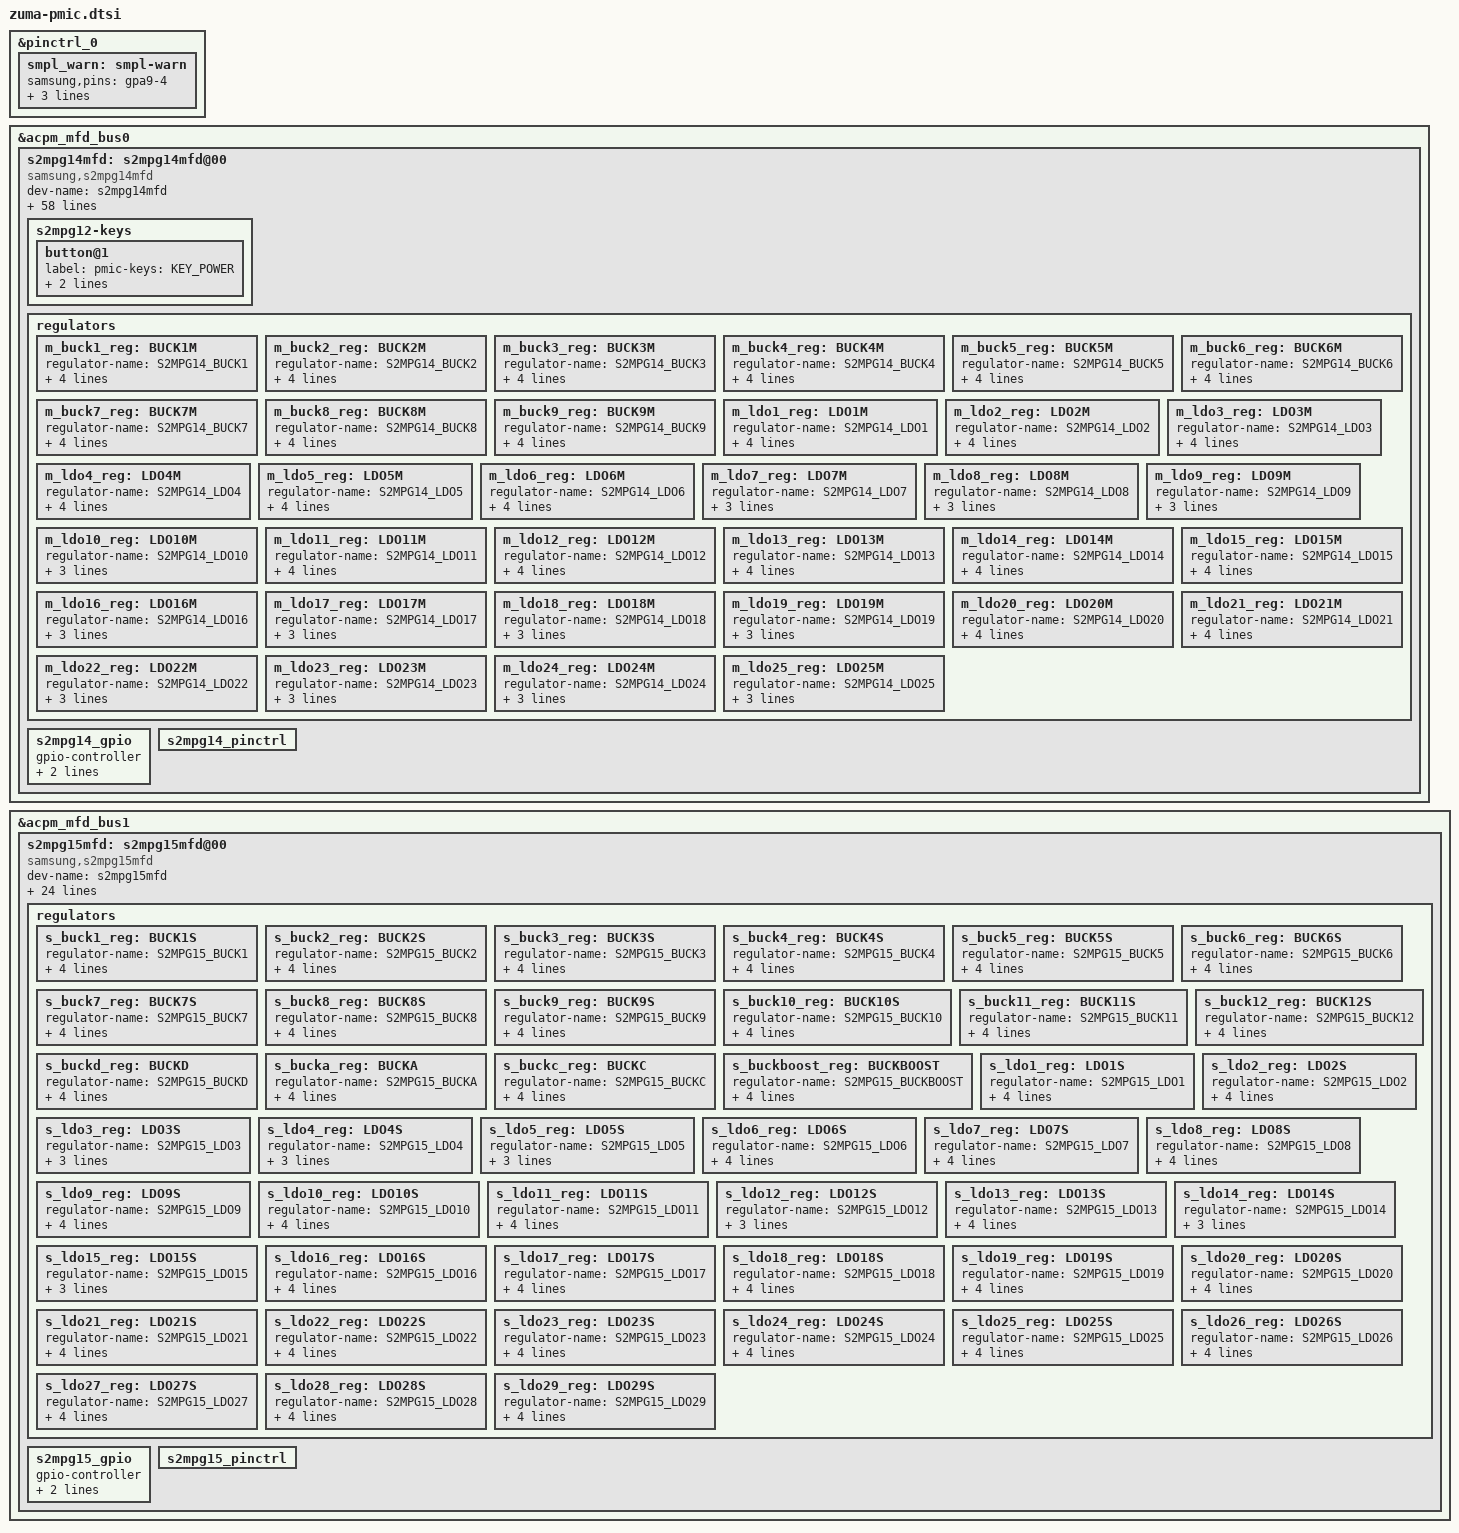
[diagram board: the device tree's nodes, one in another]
// SPDX-License-Identifier: GPL-2.0-only
/*
 * zuma pmic device tree source
 *
 * Copyright 2022 Google LLC.
 *
 */

#include <dt-bindings/power/google-power.h>
#include <dt-bindings/power/s2mpg1x-power.h>
#include <dt-bindings/regulator/samsung,s2mpg-regulator.h>

&pinctrl_0 {
	smpl_warn: smpl-warn {
		samsung,pins = "gpa9-4";
		samsung,pin-function = <EXYNOS_PIN_FUNC_EINT>;
		samsung,pin-pud = <EXYNOS_PIN_PULL_NONE>;
		samsung,pin-drv = <GS101_PIN_DRV_2_5_MA>;
	};
};

&acpm_mfd_bus0 {
	#address-cells = <1>;
	#size-cells = <0>;
	status = "okay";
	s2mpg14mfd: s2mpg14mfd@00 {
		compatible = "samsung,s2mpg14mfd";
		dev-name = "s2mpg14mfd";
		acpm-ipc-channel = <2>;
		acpm-speedy-channel = <0>;
		s2mpg14,wakeup = "enabled";
		reg = <0x1f>;
		interrupts = <1 0 0>, // SMPL_WARN
			     <1 0 1>, // OCP_WARN_CPUCL1
			     <1 0 2>, // OCP_WARN_CPUCL2
			     <1 0 3>, // SOFT_OCP_WARN_CPUCL1
			     <1 0 4>, // SOFT_OCP_WARN_CPUCL2
			     <1 0 5>, // OCP_WARN_TPU
			     <1 0 6>; // SOFT_OCP_WARN_TPU
		interrupt-parent = <&gpa0>;
		pinctrl-names = "default";
		pinctrl-0 = <&smpl_warn>;
		gpios = <&gpa9 4 GPIO_ACTIVE_HIGH>;

		#thermal-sensor-cells = <1>;

		/* SMPL_WARN */
		smpl_warn_en = <1>; /* 1 : enable , 0 : disable */
		smpl_warn_vth = <SMPL_2_9V>;
		/* SMPL_Hys[4:3] 00(Reserved), 01(200mV) */
		/*		 10(300mV), 11(Reserved) */
		smpl_warn_hys = <SMPL_HYST_200MV>;

		b2_ocp_warn_en = <OCP_WARN_DISABLE>;
		b2_ocp_warn_cnt = <OCP_WARN_2_CLOCK>;
		b2_ocp_warn_dvs_mask = <OCP_WARN_NOT_MASKED>;
		b2_ocp_warn_lvl = <OCP_WARN_LVL_2PH_8_A>;

		b3_ocp_warn_en = <OCP_WARN_DISABLE>;
		b3_ocp_warn_cnt = <OCP_WARN_2_CLOCK>;
		b3_ocp_warn_dvs_mask = <OCP_WARN_NOT_MASKED>;
		b3_ocp_warn_lvl = <OCP_WARN_LVL_3PH_13_50_A>;

		b7_ocp_warn_en = <OCP_WARN_DISABLE>;
		b7_ocp_warn_cnt = <OCP_WARN_2_CLOCK>;
		b7_ocp_warn_dvs_mask = <OCP_WARN_NOT_MASKED>;
		b7_ocp_warn_lvl = <OCP_WARN_LVL_3PH_13_50_A>;

		b2_soft_ocp_warn_en = <OCP_WARN_DISABLE>;
		b2_soft_ocp_warn_cnt = <OCP_WARN_2_CLOCK>;
		b2_soft_ocp_warn_dvs_mask = <OCP_WARN_NOT_MASKED>;
		b2_soft_ocp_warn_lvl = <OCP_WARN_LVL_2PH_8_A>;

		b3_soft_ocp_warn_en = <OCP_WARN_DISABLE>;
		b3_soft_ocp_warn_cnt = <OCP_WARN_2_CLOCK>;
		b3_soft_ocp_warn_dvs_mask = <OCP_WARN_NOT_MASKED>;
		b3_soft_ocp_warn_lvl = <OCP_WARN_LVL_3PH_13_50_A>;

		b7_soft_ocp_warn_en = <OCP_WARN_DISABLE>;
		b7_soft_ocp_warn_cnt = <OCP_WARN_2_CLOCK>;
		b7_soft_ocp_warn_dvs_mask = <OCP_WARN_NOT_MASKED>;
		b7_soft_ocp_warn_lvl = <OCP_WARN_LVL_3PH_13_50_A>;

		/* BUCK OCP Detection */
		buck_ocp_ctrl1 = <0xBB>;
		buck_ocp_ctrl2 = <0xBB>;
		buck_ocp_ctrl3 = <0xBB>;
		buck_ocp_ctrl4 = <0xBB>;
		buck_ocp_ctrl5 = <0xBB>;

		/* RTC: wtsr/smpl */
		wtsr_en = "enabled";
		coldrst_en = "enabled";
		smpl_en = "disabled";
		wtsr_timer_val = <RTC_WTSRT_2_000_SEC>;
		coldrst_timer_val = <RTC_WTSR_COLDTIMER_256_MSEC>;
		smpl_timer_val = <RTC_SMPLT_1_93_SEC>;
		sub_smpl_en = "disabled";
		check_jigon = <0>;

		/* RTC: If first boot, reset rtc to 1/1/2020 12:00:00(Wed) */
		init_time,sec = <0>;
		init_time,min = <0>;
		init_time,hour = <12>;
		init_time,mday = <1>;
		init_time,mon = <0>;
		init_time,year = <120>;
		init_time,wday = <3>;

		/* PCTRLSEL(VGPIO) 1~11 (CONTROL_SEL#) */
		sel_vgpio = <0xD3 0x1C 0xE3 0x01 0x63 0xC6
			0xE1 0x47 0x4D 0x96 0x09>;

		s2mpg12-keys {
			button@1 {
				label = "pmic-keys: KEY_POWER";
				linux,code = <116>;
				wakeup = <1>;
			};
		};

		regulators {
			m_buck1_reg: BUCK1M {
				regulator-name = "S2MPG14_BUCK1";
				regulator-min-microvolt = <450000>;
				regulator-max-microvolt = <1300000>;
				regulator-always-on;
				regulator-initial-mode = <SEC_OPMODE_ON>;
			};

			m_buck2_reg: BUCK2M {
				regulator-name = "S2MPG14_BUCK2";
				regulator-min-microvolt = <450000>;
				regulator-max-microvolt = <1300000>;
				regulator-always-on;
				regulator-initial-mode = <SEC_OPMODE_ON>;
			};

			m_buck3_reg: BUCK3M {
				regulator-name = "S2MPG14_BUCK3";
				regulator-min-microvolt = <450000>;
				regulator-max-microvolt = <1300000>;
				regulator-always-on;
				regulator-initial-mode = <SEC_OPMODE_ON>;
			};

			m_buck4_reg: BUCK4M {
				regulator-name = "S2MPG14_BUCK4";
				regulator-min-microvolt = <450000>;
				regulator-max-microvolt = <1300000>;
				regulator-always-on;
				regulator-initial-mode = <SEC_OPMODE_ON>;
			};

			m_buck5_reg: BUCK5M {
				regulator-name = "S2MPG14_BUCK5";
				regulator-min-microvolt = <450000>;
				regulator-max-microvolt = <1300000>;
				regulator-always-on;
				regulator-initial-mode = <SEC_OPMODE_ON>;
			};

			m_buck6_reg: BUCK6M {
				regulator-name = "S2MPG14_BUCK6";
				regulator-min-microvolt = <450000>;
				regulator-max-microvolt = <1500000>;
				regulator-always-on;
				regulator-initial-mode = <SEC_OPMODE_ON>;
			};

			m_buck7_reg: BUCK7M {
				regulator-name = "S2MPG14_BUCK7";
				regulator-min-microvolt = <450000>;
				regulator-max-microvolt = <1300000>;
				regulator-always-on;
				regulator-initial-mode = <SEC_OPMODE_ON>;
			};

			m_buck8_reg: BUCK8M {
				regulator-name = "S2MPG14_BUCK8";
				regulator-min-microvolt = <450000>;
				regulator-max-microvolt = <1300000>;
				regulator-always-on;
				regulator-initial-mode = <SEC_OPMODE_ON>;
			};

			m_buck9_reg: BUCK9M {
				regulator-name = "S2MPG14_BUCK9";
				regulator-min-microvolt = <450000>;
				regulator-max-microvolt = <1300000>;
				regulator-always-on;
				regulator-initial-mode = <SEC_OPMODE_ON>;
			};

			m_ldo1_reg: LDO1M {
				regulator-name = "S2MPG14_LDO1";
				regulator-min-microvolt = <450000>;
				regulator-max-microvolt = <950000>;
				regulator-always-on;
				regulator-initial-mode = <SEC_OPMODE_ON>;
			};

			m_ldo2_reg: LDO2M {
				regulator-name = "S2MPG14_LDO2";
				regulator-min-microvolt = <1600000>;
				regulator-max-microvolt = <1950000>;
				regulator-always-on;
				regulator-initial-mode = <SEC_OPMODE_ON>;
			};

			m_ldo3_reg: LDO3M {
				regulator-name = "S2MPG14_LDO3";
				regulator-min-microvolt = <450000>;
				regulator-max-microvolt = <950000>;
				regulator-always-on;
				regulator-initial-mode = <SEC_OPMODE_ON>;
			};

			m_ldo4_reg: LDO4M {
				regulator-name = "S2MPG14_LDO4";
				regulator-min-microvolt = <2500000>;
				regulator-max-microvolt = <3300000>;
				regulator-always-on;
				regulator-initial-mode = <SEC_OPMODE_ON>;
			};

			m_ldo5_reg: LDO5M {
				regulator-name = "S2MPG14_LDO5";
				regulator-min-microvolt = <1600000>;
				regulator-max-microvolt = <1950000>;
				regulator-always-on;
				regulator-initial-mode = <SEC_OPMODE_ON>;
			};

			m_ldo6_reg: LDO6M {
				regulator-name = "S2MPG14_LDO6";
				regulator-min-microvolt = <725000>;
				regulator-max-microvolt = <1300000>;
				regulator-always-on;
				regulator-initial-mode = <SEC_OPMODE_ON>;
			};

			m_ldo7_reg: LDO7M {
				regulator-name = "S2MPG14_LDO7";
				regulator-min-microvolt = <1800000>;
				regulator-max-microvolt = <3350000>;
				regulator-initial-mode = <SEC_OPMODE_ON>;
			};

			m_ldo8_reg: LDO8M {
				regulator-name = "S2MPG14_LDO8";
				regulator-min-microvolt = <450000>;
				regulator-max-microvolt = <950000>;
				regulator-initial-mode = <SEC_OPMODE_ON>;
			};

			m_ldo9_reg: LDO9M {
				regulator-name = "S2MPG14_LDO9";
				regulator-min-microvolt = <725000>;
				regulator-max-microvolt = <1300000>;
				regulator-initial-mode = <SEC_OPMODE_ON>;
			};

			m_ldo10_reg: LDO10M {
				regulator-name = "S2MPG14_LDO10";
				regulator-min-microvolt = <725000>;
				regulator-max-microvolt = <1300000>;
				regulator-initial-mode = <SEC_OPMODE_ON>;
			};

			m_ldo11_reg: LDO11M {
				regulator-name = "S2MPG14_LDO11";
				regulator-min-microvolt = <700000>;
				regulator-max-microvolt = <1300000>;
				regulator-always-on;
				regulator-initial-mode = <SEC_OPMODE_ON>;
			};

			m_ldo12_reg: LDO12M {
				regulator-name = "S2MPG14_LDO12";
				regulator-min-microvolt = <700000>;
				regulator-max-microvolt = <1300000>;
				regulator-always-on;
				regulator-initial-mode = <SEC_OPMODE_ON>;
			};

			m_ldo13_reg: LDO13M {
				regulator-name = "S2MPG14_LDO13";
				regulator-min-microvolt = <450000>;
				regulator-max-microvolt = <950000>;
				regulator-always-on;
				regulator-initial-mode = <SEC_OPMODE_ON>;
			};

			m_ldo14_reg: LDO14M {
				regulator-name = "S2MPG14_LDO14";
				regulator-min-microvolt = <2500000>;
				regulator-max-microvolt = <3300000>;
				regulator-initial-mode = <SEC_OPMODE_ON>;
				regulator-always-on;
			};

			m_ldo15_reg: LDO15M {
				regulator-name = "S2MPG14_LDO15";
				regulator-min-microvolt = <450000>;
				regulator-max-microvolt = <950000>;
				regulator-always-on;
				regulator-initial-mode = <SEC_OPMODE_ON>;
			};

			m_ldo16_reg: LDO16M {
				regulator-name = "S2MPG14_LDO16";
				regulator-min-microvolt = <725000>;
				regulator-max-microvolt = <1300000>;
				regulator-initial-mode = <SEC_OPMODE_ON>;
			};

			m_ldo17_reg: LDO17M {
				regulator-name = "S2MPG14_LDO17";
				regulator-min-microvolt = <700000>;
				regulator-max-microvolt = <1300000>;
				regulator-initial-mode = <SEC_OPMODE_ON>;
			};

			m_ldo18_reg: LDO18M {
				regulator-name = "S2MPG14_LDO18";
				regulator-min-microvolt = <725000>;
				regulator-max-microvolt = <1300000>;
				regulator-initial-mode = <SEC_OPMODE_ON>;
			};

			m_ldo19_reg: LDO19M {
				regulator-name = "S2MPG14_LDO19";
				regulator-min-microvolt = <2500000>;
				regulator-max-microvolt = <3300000>;
				regulator-initial-mode = <SEC_OPMODE_ON>;
			};

			m_ldo20_reg: LDO20M {
				regulator-name = "S2MPG14_LDO20";
				regulator-min-microvolt = <1600000>;
				regulator-max-microvolt = <1950000>;
				regulator-always-on;
				regulator-initial-mode = <SEC_OPMODE_ON>;
			};

			m_ldo21_reg: LDO21M {
				regulator-name = "S2MPG14_LDO21";
				regulator-min-microvolt = <2500000>;
				regulator-max-microvolt = <3300000>;
				regulator-always-on;
				regulator-initial-mode = <SEC_OPMODE_ON>;
			};

			m_ldo22_reg: LDO22M {
				regulator-name = "S2MPG14_LDO22";
				regulator-min-microvolt = <2500000>;
				regulator-max-microvolt = <3300000>;
				regulator-initial-mode = <SEC_OPMODE_ON>;
			};

			m_ldo23_reg: LDO23M {
				regulator-name = "S2MPG14_LDO23";
				regulator-min-microvolt = <1600000>;
				regulator-max-microvolt = <1950000>;
				regulator-initial-mode = <SEC_OPMODE_ON>;
			};

			m_ldo24_reg: LDO24M {
				regulator-name = "S2MPG14_LDO24";
				regulator-min-microvolt = <1600000>;
				regulator-max-microvolt = <1950000>;
				regulator-initial-mode = <SEC_OPMODE_ON>;
			};

			m_ldo25_reg: LDO25M {
				regulator-name = "S2MPG14_LDO25";
				regulator-min-microvolt = <1600000>;
				regulator-max-microvolt = <1950000>;
				regulator-initial-mode = <SEC_OPMODE_ON>;
			};
		};

		s2mpg14_gpio: s2mpg14_gpio {
			gpio-controller;
			#gpio-cells = <2>;
			ngpios = <6>;
			gpio-ranges = <&s2mpg14_pinctrl 0 0 6>;
		};

		s2mpg14_pinctrl: s2mpg14_pinctrl {
		};
	};
};

&acpm_mfd_bus1 {
	#address-cells = <1>;
	#size-cells = <0>;
	status = "okay";
	s2mpg15mfd: s2mpg15mfd@00 {
		compatible = "samsung,s2mpg15mfd";
		dev-name = "s2mpg15mfd";
		acpm-ipc-channel = <2>;
		acpm-speedy-channel = <1>;
		s2mpg15,wakeup = "enabled";
		reg = <0x2f>;
		interrupts = <1 0 0>, // OCP_WARN_GPU
			     <1 0 1>; // SOFT_OCP_WARN_GPU
		interrupt-parent = <&gpa0>;
		pinctrl-names = "default";

		#thermal-sensor-cells = <1>;

		b2_ocp_warn_en = <OCP_WARN_DISABLE>;
		b2_ocp_warn_cnt = <OCP_WARN_2_CLOCK>;
		b2_ocp_warn_dvs_mask = <OCP_WARN_NOT_MASKED>;
		b2_ocp_warn_lvl = <OCP_WARN_LVL_2PH_8_A>;

		b2_soft_ocp_warn_en = <OCP_WARN_DISABLE>;
		b2_soft_ocp_warn_cnt = <OCP_WARN_2_CLOCK>;
		b2_soft_ocp_warn_dvs_mask = <OCP_WARN_NOT_MASKED>;
		b2_soft_ocp_warn_lvl = <OCP_WARN_LVL_2PH_8_A>;

		/* BUCK OCP Detection */
		buck_ocp_ctrl1 = <0xBB>;
		buck_ocp_ctrl2 = <0xBA>;
		buck_ocp_ctrl3 = <0xBB>;
		buck_ocp_ctrl4 = <0xBB>;
		buck_ocp_ctrl5 = <0xBB>;
		buck_ocp_ctrl6 = <0xBB>;
		buck_ocp_ctrl7 = <0xBB>;
		buck_ocp_ctrl8 = <0xBB>;

		/* PCTRLSEL(VGPIO) 1~10 (CONTROL_SEL#) */
		sel_vgpio = <0xA3 0xF3 0x7A 0x33 0x0B 0xAB
			0x33 0x9C 0x39 0x03>;

		regulators {
			s_buck1_reg: BUCK1S {
				regulator-name = "S2MPG15_BUCK1";
				regulator-min-microvolt = <450000>;
				regulator-max-microvolt = <1300000>;
				regulator-always-on;
				regulator-initial-mode = <SEC_OPMODE_ON>;
			};

			s_buck2_reg: BUCK2S {
				regulator-name = "S2MPG15_BUCK2";
				regulator-min-microvolt = <450000>;
				regulator-max-microvolt = <1300000>;
				regulator-always-on;
				regulator-initial-mode = <SEC_OPMODE_ON>;
			};

			s_buck3_reg: BUCK3S {
				regulator-name = "S2MPG15_BUCK3";
				regulator-min-microvolt = <450000>;
				regulator-max-microvolt = <1300000>;
				regulator-always-on;
				regulator-initial-mode = <SEC_OPMODE_ON>;
			};

			s_buck4_reg: BUCK4S {
				regulator-name = "S2MPG15_BUCK4";
				regulator-min-microvolt = <450000>;
				regulator-max-microvolt = <1300000>;
				regulator-always-on;
				regulator-initial-mode = <SEC_OPMODE_ON>;
			};

			s_buck5_reg: BUCK5S {
				regulator-name = "S2MPG15_BUCK5";
				regulator-min-microvolt = <300000>;
				regulator-max-microvolt = <1300000>;
				regulator-always-on;
				regulator-initial-mode = <SEC_OPMODE_ON>;
			};

			s_buck6_reg: BUCK6S {
				regulator-name = "S2MPG15_BUCK6";
				regulator-min-microvolt = <1000000>;
				regulator-max-microvolt = <1500000>;
				regulator-always-on;
				regulator-initial-mode = <SEC_OPMODE_ON>;
			};

			s_buck7_reg: BUCK7S {
				regulator-name = "S2MPG15_BUCK7";
				regulator-min-microvolt = <1500000>;
				regulator-max-microvolt = <2200000>;
				regulator-always-on;
				regulator-initial-mode = <SEC_OPMODE_ON>;
			};

			s_buck8_reg: BUCK8S {
				regulator-name = "S2MPG15_BUCK8";
				regulator-min-microvolt = <450000>;
				regulator-max-microvolt = <1300000>;
				regulator-always-on;
				regulator-initial-mode = <SEC_OPMODE_ON>;
			};

			s_buck9_reg: BUCK9S {
				regulator-name = "S2MPG15_BUCK9";
				regulator-min-microvolt = <450000>;
				regulator-max-microvolt = <1300000>;
				regulator-always-on;
				regulator-initial-mode = <SEC_OPMODE_ON>;
			};

			s_buck10_reg: BUCK10S {
				regulator-name = "S2MPG15_BUCK10";
				regulator-min-microvolt = <450000>;
				regulator-max-microvolt = <1300000>;
				regulator-always-on;
				regulator-initial-mode = <SEC_OPMODE_ON>;
			};

			s_buck11_reg: BUCK11S {
				regulator-name = "S2MPG15_BUCK11";
				regulator-min-microvolt = <450000>;
				regulator-max-microvolt = <1300000>;
				regulator-always-on;
				regulator-initial-mode = <SEC_OPMODE_ON>;
			};

			s_buck12_reg: BUCK12S {
				regulator-name = "S2MPG15_BUCK12";
				regulator-min-microvolt = <450000>;
				regulator-max-microvolt = <1300000>;
				regulator-always-on;
				regulator-initial-mode = <SEC_OPMODE_ON>;
			};

			s_buckd_reg: BUCKD {
				regulator-name = "S2MPG15_BUCKD";
				regulator-min-microvolt = <2400000>;
				regulator-max-microvolt = <3300000>;
				regulator-always-on;
				regulator-initial-mode = <SEC_OPMODE_ON>;
			};

			s_bucka_reg: BUCKA {
				regulator-name = "S2MPG15_BUCKA";
				regulator-min-microvolt = <1700000>;
				regulator-max-microvolt = <2100000>;
				regulator-always-on;
				regulator-initial-mode = <SEC_OPMODE_ON>;
			};

			s_buckc_reg: BUCKC {
				regulator-name = "S2MPG15_BUCKC";
				regulator-min-microvolt = <450000>;
				regulator-max-microvolt = <1350000>;
				regulator-always-on;
				regulator-initial-mode = <SEC_OPMODE_ON>;
			};

			s_buckboost_reg: BUCKBOOST {
				regulator-name = "S2MPG15_BUCKBOOST";
				regulator-min-microvolt = <3000000>;
				regulator-max-microvolt = <3600000>;
				regulator-always-on;
				regulator-initial-mode = <SEC_OPMODE_ON>;
			};

			s_ldo1_reg: LDO1S {
				regulator-name = "S2MPG15_LDO1";
				regulator-min-microvolt = <700000>;
				regulator-max-microvolt = <1300000>;
				regulator-always-on;
				regulator-initial-mode = <SEC_OPMODE_ON>;
			};

			s_ldo2_reg: LDO2S {
				regulator-name = "S2MPG15_LDO2";
				regulator-min-microvolt = <700000>;
				regulator-max-microvolt = <1300000>;
				regulator-always-on;
				regulator-initial-mode = <SEC_OPMODE_ON>;
			};

			s_ldo3_reg: LDO3S {
				regulator-name = "S2MPG15_LDO3";
				regulator-min-microvolt = <725000>;
				regulator-max-microvolt = <1300000>;
				regulator-initial-mode = <SEC_OPMODE_ON>;
			};

			s_ldo4_reg: LDO4S {
				regulator-name = "S2MPG15_LDO4";
				regulator-min-microvolt = <1600000>;
				regulator-max-microvolt = <1950000>;
				regulator-initial-mode = <SEC_OPMODE_ON>;
			};

			s_ldo5_reg: LDO5S {
				regulator-name = "S2MPG15_LDO5";
				regulator-min-microvolt = <2500000>;
				regulator-max-microvolt = <3300000>;
				regulator-initial-mode = <SEC_OPMODE_ON>;
			};

			s_ldo6_reg: LDO6S {
				regulator-name = "S2MPG15_LDO6";
				regulator-min-microvolt = <2500000>;
				regulator-max-microvolt = <3300000>;
				regulator-boot-on;
				regulator-initial-mode = <SEC_OPMODE_ON>;
			};

			s_ldo7_reg: LDO7S {
				regulator-name = "S2MPG15_LDO7";
				regulator-min-microvolt = <1600000>;
				regulator-max-microvolt = <1950000>;
				regulator-boot-on;
				regulator-initial-mode = <SEC_OPMODE_ON>;
			};

			s_ldo8_reg: LDO8S {
				regulator-name = "S2MPG15_LDO8";
				regulator-min-microvolt = <2500000>;
				regulator-max-microvolt = <3300000>;
				regulator-always-on;
				regulator-initial-mode = <SEC_OPMODE_ON>;
			};

			s_ldo9_reg: LDO9S {
				regulator-name = "S2MPG15_LDO9";
				regulator-min-microvolt = <725000>;
				regulator-max-microvolt = <1300000>;
				regulator-always-on;
				regulator-initial-mode = <SEC_OPMODE_ON>;
			};

			s_ldo10_reg: LDO10S {
				regulator-name = "S2MPG15_LDO10";
				regulator-min-microvolt = <1600000>;
				regulator-max-microvolt = <1950000>;
				regulator-always-on;
				regulator-initial-mode = <SEC_OPMODE_ON>;
			};

			s_ldo11_reg: LDO11S {
				regulator-name = "S2MPG15_LDO11";
				regulator-min-microvolt = <1600000>;
				regulator-max-microvolt = <1950000>;
				regulator-always-on;
				regulator-initial-mode = <SEC_OPMODE_ON>;
			};

			s_ldo12_reg: LDO12S {
				regulator-name = "S2MPG15_LDO12";
				regulator-min-microvolt = <1600000>;
				regulator-max-microvolt = <1950000>;
				regulator-initial-mode = <SEC_OPMODE_ON>;
			};

			s_ldo13_reg: LDO13S {
				regulator-name = "S2MPG15_LDO13";
				regulator-min-microvolt = <1600000>;
				regulator-max-microvolt = <1950000>;
				regulator-always-on;
				regulator-initial-mode = <SEC_OPMODE_ON>;
			};

			s_ldo14_reg: LDO14S {
				regulator-name = "S2MPG15_LDO14";
				regulator-min-microvolt = <1600000>;
				regulator-max-microvolt = <1950000>;
				regulator-initial-mode = <SEC_OPMODE_ON>;
			};

			s_ldo15_reg: LDO15S {
				regulator-name = "S2MPG15_LDO15";
				regulator-min-microvolt = <2500000>;
				regulator-max-microvolt = <3300000>;
				regulator-initial-mode = <SEC_OPMODE_ON>;
			};

			s_ldo16_reg: LDO16S {
				regulator-name = "S2MPG15_LDO16";
				regulator-min-microvolt = <2500000>;
				regulator-max-microvolt = <3300000>;
				regulator-always-on;
				regulator-initial-mode = <SEC_OPMODE_ON>;
			};

			s_ldo17_reg: LDO17S {
				regulator-name = "S2MPG15_LDO17";
				regulator-min-microvolt = <1600000>;
				regulator-max-microvolt = <19500000>;
				regulator-always-on;
				regulator-initial-mode = <SEC_OPMODE_ON>;
			};

			s_ldo18_reg: LDO18S {
				regulator-name = "S2MPG15_LDO18";
				regulator-min-microvolt = <2500000>;
				regulator-max-microvolt = <3300000>;
				regulator-always-on;
				regulator-initial-mode = <SEC_OPMODE_ON>;
			};

			s_ldo19_reg: LDO19S {
				regulator-name = "S2MPG15_LDO19";
				regulator-min-microvolt = <1600000>;
				regulator-max-microvolt = <1950000>;
				regulator-always-on;
				regulator-initial-mode = <SEC_OPMODE_ON>;
			};

			s_ldo20_reg: LDO20S {
				regulator-name = "S2MPG15_LDO20";
				regulator-min-microvolt = <1600000>;
				regulator-max-microvolt = <1950000>;
				regulator-always-on;
				regulator-initial-mode = <SEC_OPMODE_ON>;
			};

			s_ldo21_reg: LDO21S {
				regulator-name = "S2MPG15_LDO21";
				regulator-min-microvolt = <725000>;
				regulator-max-microvolt = <1300000>;
				regulator-always-on;
				regulator-initial-mode = <SEC_OPMODE_ON>;
			};

			s_ldo22_reg: LDO22S {
				regulator-name = "S2MPG15_LDO22";
				regulator-min-microvolt = <1600000>;
				regulator-max-microvolt = <1950000>;
				regulator-always-on;
				regulator-initial-mode = <SEC_OPMODE_ON>;
			};

			s_ldo23_reg: LDO23S {
				regulator-name = "S2MPG15_LDO23";
				regulator-min-microvolt = <700000>;
				regulator-max-microvolt = <1300000>;
				regulator-always-on;
				regulator-initial-mode = <SEC_OPMODE_ON>;
			};

			s_ldo24_reg: LDO24S {
				regulator-name = "S2MPG15_LDO24";
				regulator-min-microvolt = <725000>;
				regulator-max-microvolt = <1300000>;
				regulator-always-on;
				regulator-initial-mode = <SEC_OPMODE_ON>;
			};

			s_ldo25_reg: LDO25S {
				regulator-name = "S2MPG15_LDO25";
				regulator-min-microvolt = <2500000>;
				regulator-max-microvolt = <3300000>;
				regulator-always-on;
				regulator-initial-mode = <SEC_OPMODE_ON>;
			};

			s_ldo26_reg: LDO26S {
				regulator-name = "S2MPG15_LDO26";
				regulator-min-microvolt = <2500000>;
				regulator-max-microvolt = <3300000>;
				regulator-always-on;
				regulator-initial-mode = <SEC_OPMODE_ON>;
			};

			s_ldo27_reg: LDO27S {
				regulator-name = "S2MPG15_LDO27";
				regulator-min-microvolt = <1600000>;
				regulator-max-microvolt = <1950000>;
				regulator-always-on;
				regulator-initial-mode = <SEC_OPMODE_ON>;
			};

			s_ldo28_reg: LDO28S {
				regulator-name = "S2MPG15_LDO28";
				regulator-min-microvolt = <2500000>;
				regulator-max-microvolt = <3300000>;
				regulator-always-on;
				regulator-initial-mode = <SEC_OPMODE_ON>;
			};

			s_ldo29_reg: LDO29S {
				regulator-name = "S2MPG15_LDO29";
				regulator-min-microvolt = <1600000>;
				regulator-max-microvolt = <1950000>;
				regulator-always-on;
				regulator-initial-mode = <SEC_OPMODE_ON>;
			};
		};

		s2mpg15_gpio: s2mpg15_gpio {
			gpio-controller;
			#gpio-cells = <2>;
			ngpios = <6>;
			gpio-ranges = <&s2mpg15_pinctrl 0 0 6>;
		};

		s2mpg15_pinctrl: s2mpg15_pinctrl {
		};
	};
};
